# MSP430FR2522 register map
Vendor: msp430gen; File version: v0.4.0-28-gb0087ce-dirty
Registers are 16-bit, read-write, reset 0x0 unless marked. A register's access mark holds for its fields unless they carry their own. Offsets are from the block's base; [hi:lo] are bit positions; {n}, {i} and the like mark numbered series.

## RTC
Base 0x00000300
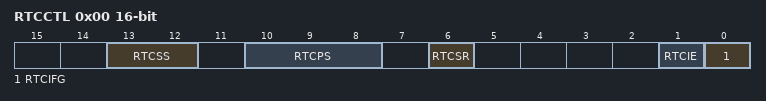
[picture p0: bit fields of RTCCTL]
0x00 RTCCTL — RTCCTL0 Register
  [13:12] RTCSS — Real-time clock source select
    0=DISABLED; 1=SMCLK; 2=XT1CLK; 3=VLOCLK
  [10:8] RTCPS — Real-time clock pre-divider select
    0=1; 1=10; 2=100; 3=1000; 4=16; 5=64; 6=256; 7=1024
  [6] RTCSR — Real-time software reset. This is a write only bit and is always read with logic 0. 0b = Write 0 has no effect
    0=Write 0 has no effect; 1=Write 1 to this bit clears the counter value and reloads the shadow register value from the modulo register at the next tick of the selected source clock. No overflow event or interrupt is generated.
  [1] RTCIE — Real-time interrupt enable
    0=Interrupt disabled; 1=Interrupt enabled
  [0] RTCIFG ro — Real-time interrupt flag. This bit reports the status of a pending interrupt. This read only bit can be cleared by reading RTCIV register.
    0=No interrupt pending; 1=Interrupt pending
0x04 RTCIV — Real-Time Clock Interrupt Vector Register
  [15:0] RTCIV ro — Real-time clock interrupt vector value
    0=NONE (No interrupt pending); 2=RTCIFG (upt Source: RTC Counter Overflow; Interrupt Flag: RTCIFG)
0x08 RTCMOD — RTC Counter Modulo Register
0x0C RTCCNT — RTC Counter Register

## TA0
Base 0x00000380
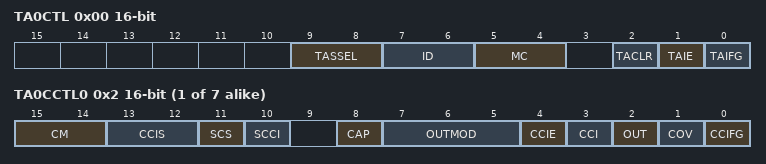
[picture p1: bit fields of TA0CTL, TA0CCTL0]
0x00 TA0CTL — TimerAx Control Register
  [9:8] TASSEL — TimerA clock source select
    0=TACLK (TAxCLK); 1=ACLK; 2=SMCLK; 3=INCLK
  [7:6] ID — Input divider
    0=1; 1=2; 2=4; 3=8
  [5:4] MC — Mode control
    0=STOP (Stop mode: Timer is halted); 1=UP (Up mode: Timer counts up to TAxCCR0); 2=CONTINUOUS (Continuous mode: Timer counts up to 0FFFFh); 3=UPDOWN (Up/down mode: Timer counts up to TAxCCR0 then down to 0000h)
  [2] TACLR — TimerA clear
  [1] TAIE — TimerA interrupt enable
    0=Interrupt disabled; 1=Interrupt enabled
  [0] TAIFG — TimerA interrupt flag
    0=No interrupt pending; 1=Interrupt pending
{0x2+2i} TA0CCTL{i} (i=0..6) — Timer_A Capture/Compare Control Register
  [15:14] CM — Capture mode
    0=NONE (No capture); 1=RISING (Capture on rising edge); 2=FALLING (Capture on falling edge); 3=BOTH (Capture on both rising and falling edges)
  [13:12] CCIS — Capture/compare input select
    0=CCIA (CCIxA); 1=CCIB (CCIxB); 2=GND; 3=VCC
  [11] SCS — Synchronize capture source
    0=ASYNC (Asynchronous capture); 1=SYNC (Synchronous capture)
  [10] SCCI — Synchronized capture/compare input
  [8] CAP — Capture mode
    0=COMPARE (Compare mode); 1=CAPTURE (Capture mode)
  [7:5] OUTMOD — Output mode
    0=OUT bit value; 1=Set; 2=Toggle/reset; 3=Set/reset; 4=Toggle; 5=Reset; 6=Toggle/set; 7=Reset/set
  [4] CCIE — Capture/compare interrupt enable
    0=Interrupt disabled; 1=Interrupt enabled
  [3] CCI ro — Capture/compare input
  [2] OUT — Output
    0=LOW (Output low); 1=HIGH (Output high)
  [1] COV — Capture overflow
    0=No capture overflow occurred; 1=Capture overflow occurred
  [0] CCIFG — Capture/compare interrupt flag
    0=No interrupt pending; 1=Interrupt pending
0x10 TA0R — TimerA register
{0x12+2i} TA0CCR{i} (i=0..6) — Timer_A Capture/Compare Register
0x20 TA0EX0 — TimerAx Expansion 0 Register
  [2:0] TAIDEX — Input divider expansion
    {v}=Divide by {v+1} (v=0..7)
0x2E TA0IV — TimerAx Interrupt Vector Register
  [15:0] TAIV ro — TimerA interrupt vector value
    0=NONE (No interrupt pending); 2=TACCR1 (Interrupt Source: Capture/compare 1; Interrupt Flag: TAxCCR1 CCIFG; Interrupt Priority: Highest); 4=TACCR2 (Interrupt Source: Capture/compare 2; Interrupt Flag: TAxCCR2 CCIFG); 6=TACCR3 (Interrupt Source: Capture/compare 3; Interrupt Flag: TAxCCR3 CCIFG); 8=TACCR4 (Interrupt Source: Capture/compare 4; Interrupt Flag: TAxCCR4 CCIFG); 10=TACCR5 (Interrupt Source: Capture/compare 5; Interrupt Flag: TAxCCR5 CCIFG); 12=TACCR6 (Interrupt Source: Capture/compare 6; Interrupt Flag: TAxCCR6 CCIFG); 14=TAIFG (Interrupt Source: Timer overflow; Interrupt Flag: TAxCTL TAIFG; Interrupt Priority: Lowest)

## TA1
Base 0x000003C0
Registers as TA0 (with TA0 read as TA1).
